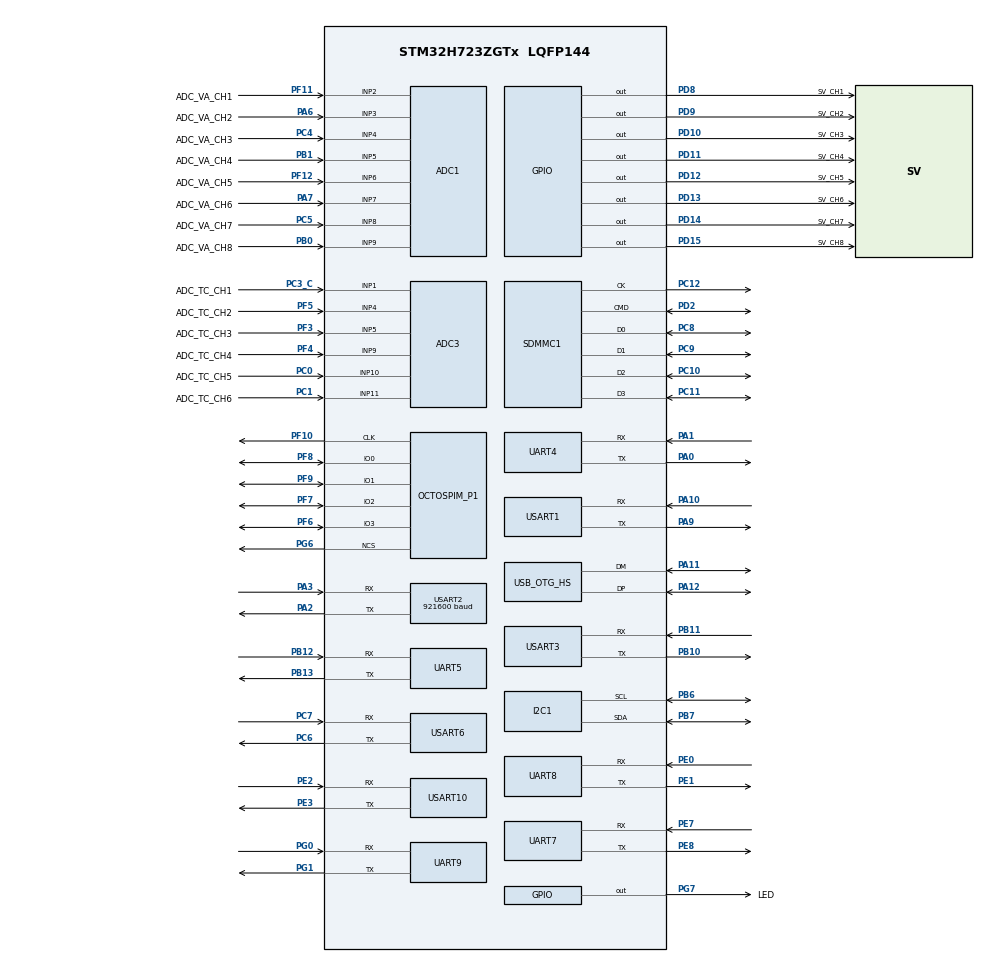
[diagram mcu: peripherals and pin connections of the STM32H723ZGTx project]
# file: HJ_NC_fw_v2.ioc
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ADC1.Channel-0\#ChannelRegularConversion=ADC_CHANNEL_2
ADC1.NbrOfConversionFlag=1
ADC1.OffsetNumber-0\#ChannelRegularConversion=ADC_OFFSET_NONE
ADC1.OffsetSignedSaturation-0\#ChannelRegularConversion=DISABLE
ADC1.Rank-0\#ChannelRegularConversion=1
ADC1.SamplingTime-0\#ChannelRegularConversion=ADC_SAMPLETIME_1CYCLE_5
ADC1.master=1
ADC3.Channel-0\#ChannelRegularConversion=ADC_CHANNEL_1
ADC3.NbrOfConversionFlag=1
ADC3.OffsetNumber-0\#ChannelRegularConversion=ADC_OFFSET_NONE
ADC3.OffsetSign-0\#ChannelRegularConversion=ADC3_OFFSET_SIGN_NEGATIVE
ADC3.Rank-0\#ChannelRegularConversion=1
ADC3.SamplingTime-0\#ChannelRegularConversion=ADC3_SAMPLETIME_2CYCLES_5
CORTEX_M7.default_mode_Activation=0
I2C1.Timing=0x60404E72
Mcu.Family=STM32H7
Mcu.Name=STM32H723ZGTx
Mcu.Package=LQFP144
NVIC.OTG_HS_IRQn=true\:0\:0\:false\:false\:true\:false\:true\:true
NVIC.PriorityGroup=NVIC_PRIORITYGROUP_4
NVIC.UART4_IRQn=true\:0\:0\:false\:false\:true\:true\:true\:true
NVIC.UART5_IRQn=true\:0\:0\:false\:false\:true\:true\:true\:true
NVIC.USART2_IRQn=true\:0\:0\:false\:false\:true\:true\:true\:true
NVIC.USART3_IRQn=true\:0\:0\:false\:false\:true\:true\:true\:true
OCTOSPI1.ClockMode=HAL_OSPI_CLOCK_MODE_3
OCTOSPI1.ClockPrescaler=2
OCTOSPI1.DeviceSize=23
OCTOSPI1.FifoThreshold=8
OCTOSPI1.FreeRunningClock=HAL_OSPI_FREERUNCLK_DISABLE
OCTOSPI1.SampleShifting=HAL_OSPI_SAMPLE_SHIFTING_HALFCYCLE
PA0.Mode=Asynchronous
PA0.Signal=UART4_TX
PA1.Mode=Asynchronous
PA1.Signal=UART4_RX
PA10.GPIO_Speed=GPIO_SPEED_FREQ_VERY_HIGH
PA10.Mode=Asynchronous
PA10.Signal=USART1_RX
PA11.Mode=Device_Only_FS
PA11.Signal=USB_OTG_HS_DM
PA12.Mode=Device_Only_FS
PA12.Signal=USB_OTG_HS_DP
PA13(JTMS/SWDIO).Mode=Serial_Wire
PA13(JTMS/SWDIO).Signal=DEBUG_JTMS-SWDIO
PA14(JTCK/SWCLK).Mode=Serial_Wire
PA14(JTCK/SWCLK).Signal=DEBUG_JTCK-SWCLK
PA2.Mode=Asynchronous
PA2.Signal=USART2_TX
PA3.Mode=Asynchronous
PA3.Signal=USART2_RX
PA6.GPIO_Label=ADC_VA_CH2
PA6.Signal=ADCx_INP3
PA7.GPIO_Label=ADC_VA_CH6
PA7.Signal=ADCx_INP7
PA9.GPIO_Speed=GPIO_SPEED_FREQ_VERY_HIGH
PA9.Mode=Asynchronous
PA9.Signal=USART1_TX
PB0.GPIO_Label=ADC_VA_CH8
PB0.Signal=ADCx_INP9
PB1.GPIO_Label=ADC_VA_CH4
PB1.Signal=ADCx_INP5
PB10.Mode=Asynchronous
PB10.Signal=USART3_TX
PB11.Mode=Asynchronous
PB11.Signal=USART3_RX
PB12.Mode=Asynchronous
PB12.Signal=UART5_RX
PB13.Mode=Asynchronous
PB13.Signal=UART5_TX
PB6.Mode=I2C
PB6.Signal=I2C1_SCL
PB7.Mode=I2C
PB7.Signal=I2C1_SDA
PC0.GPIO_Label=ADC_TC_CH5
PC0.Signal=ADCx_INP10
PC1.GPIO_Label=ADC_TC_CH6
PC1.Signal=ADCx_INP11
PC10.Mode=SD_4_bits_Wide_bus
PC10.Signal=SDMMC1_D2
PC11.Mode=SD_4_bits_Wide_bus
PC11.Signal=SDMMC1_D3
PC12.Mode=SD_4_bits_Wide_bus
PC12.Signal=SDMMC1_CK
PC14-OSC32_IN.Mode=LSE-External-Oscillator
PC14-OSC32_IN.Signal=RCC_OSC32_IN
PC15-OSC32_OUT.Mode=LSE-External-Oscillator
PC15-OSC32_OUT.Signal=RCC_OSC32_OUT
PC3_C.GPIO_Label=ADC_TC_CH1
PC3_C.Mode=IN1-Single-Ended
PC3_C.Signal=ADC3_INP1
PC4.GPIO_Label=ADC_VA_CH3
PC4.Signal=ADCx_INP4
PC5.GPIO_Label=ADC_VA_CH7
PC5.Signal=ADCx_INP8
PC6.Mode=Asynchronous
PC6.Signal=USART6_TX
PC7.Mode=Asynchronous
PC7.Signal=USART6_RX
PC8.Mode=SD_4_bits_Wide_bus
PC8.Signal=SDMMC1_D0
PC9.Mode=SD_4_bits_Wide_bus
PC9.Signal=SDMMC1_D1
PD10.GPIO_Label=SV_CH3
PD10.Signal=GPIO_Output
PD11.GPIO_Label=SV_CH4
PD11.Signal=GPIO_Output
PD12.GPIO_Label=SV_CH5
PD12.Signal=GPIO_Output
PD13.GPIO_Label=SV_CH6
PD13.Signal=GPIO_Output
PD14.GPIO_Label=SV_CH7
PD14.Signal=GPIO_Output
PD15.GPIO_Label=SV_CH8
PD15.Signal=GPIO_Output
PD2.Mode=SD_4_bits_Wide_bus
PD2.Signal=SDMMC1_CMD
PD8.GPIO_Label=SV_CH1
PD8.Signal=GPIO_Output
PD9.GPIO_Label=SV_CH2
PD9.Signal=GPIO_Output
PE0.Mode=Asynchronous
PE0.Signal=UART8_RX
PE1.Mode=Asynchronous
PE1.Signal=UART8_TX
PE2.Mode=Asynchronous
PE2.Signal=USART10_RX
PE3.Mode=Asynchronous
PE3.Signal=USART10_TX
PE7.Mode=Asynchronous
PE7.Signal=UART7_RX
PE8.Mode=Asynchronous
PE8.Signal=UART7_TX
PF10.Mode=O1_P1_CLK
PF10.Signal=OCTOSPIM_P1_CLK
PF11.GPIO_Label=ADC_VA_CH1
PF11.Mode=IN2-Single-Ended
PF11.Signal=ADC1_INP2
PF12.GPIO_Label=ADC_VA_CH5
PF12.Mode=IN6-Single-Ended
PF12.Signal=ADC1_INP6
PF3.GPIO_Label=ADC_TC_CH3
PF3.Mode=IN5-Single-Ended
PF3.Signal=ADC3_INP5
PF4.GPIO_Label=ADC_TC_CH4
PF4.Mode=IN9-Single-Ended
PF4.Signal=ADC3_INP9
PF5.GPIO_Label=ADC_TC_CH2
PF5.Mode=IN4-Single-Ended
PF5.Signal=ADC3_INP4
PF6.Mode=OCTOSPI1_IOL_Port1L
PF6.Signal=OCTOSPIM_P1_IO3
PF7.Mode=OCTOSPI1_IOL_Port1L
PF7.Signal=OCTOSPIM_P1_IO2
PF8.Mode=OCTOSPI1_IOL_Port1L
PF8.Signal=OCTOSPIM_P1_IO0
PF9.Mode=OCTOSPI1_IOL_Port1L
PF9.Signal=OCTOSPIM_P1_IO1
PG0.Mode=Asynchronous
PG0.Signal=UART9_RX
PG1.Mode=Asynchronous
PG1.Signal=UART9_TX
PG6.Mode=OCTOSPI1_Port1_NCS
PG6.Signal=OCTOSPIM_P1_NCS
PG7.GPIO_Label=LED
PG7.Signal=GPIO_Output
PH0-OSC_IN.Mode=HSE-External-Oscillator
PH0-OSC_IN.Signal=RCC_OSC_IN
PH1-OSC_OUT.Mode=HSE-External-Oscillator
PH1-OSC_OUT.Signal=RCC_OSC_OUT
ProjectManager.HeapSize=0x200
ProjectManager.StackSize=0x400
ProjectManager.TargetToolchain=STM32CubeIDE
RCC.ADCFreq_Value=100000000
RCC.APB1Freq_Value=137500000
RCC.APB2Freq_Value=137500000
RCC.APB3Freq_Value=137500000
RCC.APB4Freq_Value=137500000
RCC.CortexFreq_Value=550000000
RCC.D1PPRE=RCC_APB3_DIV2
RCC.D2PPRE1=RCC_APB1_DIV2
RCC.D2PPRE2=RCC_APB2_DIV2
RCC.D3PPRE=RCC_APB4_DIV2
RCC.DIVM1=10
RCC.DIVM2=16
RCC.DIVN1=220
RCC.DIVN2=128
RCC.DIVP1=1
RCC.DIVQ1=5
RCC.HCLKFreq_Value=275000000
RCC.HPRE=RCC_HCLK_DIV2
RCC.PLLSourceVirtual=RCC_PLLSOURCE_HSE
RCC.RTCClockSelection=RCC_RTCCLKSOURCE_LSE
RCC.SYSCLKFreq_VALUE=550000000
RCC.SYSCLKSource=RCC_SYSCLKSOURCE_PLLCLK
RCC.USBCLockSelection=RCC_USBCLKSOURCE_HSI48
RCC.USBFreq_Value=48000000
SDMMC1.ClockDiv=4
SH.ADCx_INP10.0=ADC3_INP10,IN10-Single-Ended
SH.ADCx_INP11.0=ADC3_INP11,IN11-Single-Ended
SH.ADCx_INP3.0=ADC1_INP3,IN3-Single-Ended
SH.ADCx_INP4.0=ADC1_INP4,IN4-Single-Ended
SH.ADCx_INP5.0=ADC1_INP5,IN5-Single-Ended
SH.ADCx_INP7.0=ADC1_INP7,IN7-Single-Ended
SH.ADCx_INP8.0=ADC1_INP8,IN8-Single-Ended
SH.ADCx_INP9.0=ADC1_INP9,IN9-Single-Ended
USART1.VirtualMode-Asynchronous=VM_ASYNC
USART10.VirtualMode-Asynchronous=VM_ASYNC
USART2.BaudRate=921600
USART2.VirtualMode-Asynchronous=VM_ASYNC
USART3.VirtualMode-Asynchronous=VM_ASYNC
USART6.VirtualMode-Asynchronous=VM_ASYNC
USB_DEVICE.CLASS_NAME_HS=CDC
USB_DEVICE.VirtualMode=Cdc
USB_DEVICE.VirtualModeHS=Cdc_HS
USB_OTG_HS.VirtualMode-Device_Only_FS=Device_Only_FS
VP_MEMORYMAP_VS_MEMORYMAP.Mode=CurAppReg
VP_OCTOSPI1_VS_quad.Mode=quad_mode
VP_RTC_VS_RTC_Activate.Mode=RTC_Enabled
VP_USB_DEVICE_VS_USB_DEVICE_CDC_HS.Mode=CDC_HS
board=custom

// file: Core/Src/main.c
/* USER CODE BEGIN Header */
/**
  ******************************************************************************
  * @file           : main.c
  * @brief          : Main program body
  ******************************************************************************
  * @attention
  *
  * Copyright (c) 2025 STMicroelectronics.
  * All rights reserved.
  *
  * This software is licensed under terms that can be found in the LICENSE file
  * in the root directory of this software component.
  * If no LICENSE file comes with this software, it is provided AS-IS.
  *
  ******************************************************************************
  */
/* USER CODE END Header */
#include "main.h"
#include "usb_device.h"

/* USER CODE BEGIN Includes */
#include "application.h"
/* USER CODE END Includes */

ADC_HandleTypeDef hadc1;
ADC_HandleTypeDef hadc3;

I2C_HandleTypeDef hi2c1;

OSPI_HandleTypeDef hospi1;

RTC_HandleTypeDef hrtc;

SD_HandleTypeDef hsd1;

UART_HandleTypeDef huart4;
UART_HandleTypeDef huart5;
UART_HandleTypeDef huart7;
UART_HandleTypeDef huart8;
UART_HandleTypeDef huart9;
UART_HandleTypeDef huart1;
UART_HandleTypeDef huart2;
UART_HandleTypeDef huart3;
UART_HandleTypeDef huart6;
UART_HandleTypeDef huart10;

void SystemClock_Config(void);
void PeriphCommonClock_Config(void);
static void MX_GPIO_Init(void);
static void MX_USART1_UART_Init(void);
static void MX_OCTOSPI1_Init(void);
static void MX_RTC_Init(void);
static void MX_SDMMC1_SD_Init(void);
static void MX_ADC1_Init(void);
static void MX_ADC3_Init(void);
static void MX_UART4_Init(void);
static void MX_UART5_Init(void);
static void MX_UART7_Init(void);
static void MX_UART8_Init(void);
static void MX_UART9_Init(void);
static void MX_USART2_UART_Init(void);
static void MX_USART3_UART_Init(void);
static void MX_USART6_UART_Init(void);
static void MX_USART10_UART_Init(void);
static void MX_I2C1_Init(void);

int main(void)
{

  /* MCU Configuration--------------------------------------------------------*/

  /* Reset of all peripherals, Initializes the Flash interface and the Systick. */
  HAL_Init();

  /* Configure the system clock */
  SystemClock_Config();

  /* Configure the peripherals common clocks */
  PeriphCommonClock_Config();

  /* Initialize all configured peripherals */
  MX_GPIO_Init();
  MX_USART1_UART_Init();
  MX_OCTOSPI1_Init();
  MX_RTC_Init();
  MX_SDMMC1_SD_Init();
  MX_USB_DEVICE_Init();
  MX_ADC1_Init();
  MX_ADC3_Init();
  MX_UART4_Init();
  MX_UART5_Init();
  MX_UART7_Init();
  MX_UART8_Init();
  MX_UART9_Init();
  MX_USART2_UART_Init();
  MX_USART3_UART_Init();
  MX_USART6_UART_Init();
  MX_USART10_UART_Init();
  MX_I2C1_Init();

  /* Infinite loop */
  /* USER CODE BEGIN WHILE */
  setup();
  while (1)
  {
	loop();
    /* USER CODE END WHILE */

  }
}

void SystemClock_Config(void)
{
  RCC_OscInitTypeDef RCC_OscInitStruct = {0};
  RCC_ClkInitTypeDef RCC_ClkInitStruct = {0};

  /** Supply configuration update enable
  */
  HAL_PWREx_ConfigSupply(PWR_LDO_SUPPLY);

  /** Configure the main internal regulator output voltage
  */
  __HAL_PWR_VOLTAGESCALING_CONFIG(PWR_REGULATOR_VOLTAGE_SCALE0);

  while(!__HAL_PWR_GET_FLAG(PWR_FLAG_VOSRDY)) {}

  /** Configure LSE Drive Capability
  */
  HAL_PWR_EnableBkUpAccess();
  __HAL_RCC_LSEDRIVE_CONFIG(RCC_LSEDRIVE_LOW);

  /** Initializes the RCC Oscillators according to the specified parameters
  * in the RCC_OscInitTypeDef structure.
  */
  RCC_OscInitStruct.OscillatorType = RCC_OSCILLATORTYPE_HSI48|RCC_OSCILLATORTYPE_HSE
                              |RCC_OSCILLATORTYPE_LSE;
  RCC_OscInitStruct.HSEState = RCC_HSE_ON;
  RCC_OscInitStruct.LSEState = RCC_LSE_ON;
  RCC_OscInitStruct.HSI48State = RCC_HSI48_ON;
  RCC_OscInitStruct.PLL.PLLState = RCC_PLL_ON;
  RCC_OscInitStruct.PLL.PLLSource = RCC_PLLSOURCE_HSE;
  RCC_OscInitStruct.PLL.PLLM = 10;
  RCC_OscInitStruct.PLL.PLLN = 220;
  RCC_OscInitStruct.PLL.PLLP = 1;
  RCC_OscInitStruct.PLL.PLLQ = 5;
  RCC_OscInitStruct.PLL.PLLR = 2;
  RCC_OscInitStruct.PLL.PLLRGE = RCC_PLL1VCIRANGE_1;
  RCC_OscInitStruct.PLL.PLLVCOSEL = RCC_PLL1VCOWIDE;
  RCC_OscInitStruct.PLL.PLLFRACN = 0;
  if (HAL_RCC_OscConfig(&RCC_OscInitStruct) != HAL_OK)
  {
    Error_Handler();
  }

  /** Initializes the CPU, AHB and APB buses clocks
  */
  RCC_ClkInitStruct.ClockType = RCC_CLOCKTYPE_HCLK|RCC_CLOCKTYPE_SYSCLK
                              |RCC_CLOCKTYPE_PCLK1|RCC_CLOCKTYPE_PCLK2
                              |RCC_CLOCKTYPE_D3PCLK1|RCC_CLOCKTYPE_D1PCLK1;
  RCC_ClkInitStruct.SYSCLKSource = RCC_SYSCLKSOURCE_PLLCLK;
  RCC_ClkInitStruct.SYSCLKDivider = RCC_SYSCLK_DIV1;
  RCC_ClkInitStruct.AHBCLKDivider = RCC_HCLK_DIV2;
  RCC_ClkInitStruct.APB3CLKDivider = RCC_APB3_DIV2;
  RCC_ClkInitStruct.APB1CLKDivider = RCC_APB1_DIV2;
  RCC_ClkInitStruct.APB2CLKDivider = RCC_APB2_DIV2;
  RCC_ClkInitStruct.APB4CLKDivider = RCC_APB4_DIV2;

  if (HAL_RCC_ClockConfig(&RCC_ClkInitStruct, FLASH_LATENCY_3) != HAL_OK)
  {
    Error_Handler();
  }
}

void PeriphCommonClock_Config(void)
{
  RCC_PeriphCLKInitTypeDef PeriphClkInitStruct = {0};

  /** Initializes the peripherals clock
  */
  PeriphClkInitStruct.PeriphClockSelection = RCC_PERIPHCLK_ADC;
  PeriphClkInitStruct.PLL2.PLL2M = 16;
  PeriphClkInitStruct.PLL2.PLL2N = 128;
  PeriphClkInitStruct.PLL2.PLL2P = 2;
  PeriphClkInitStruct.PLL2.PLL2Q = 2;
  PeriphClkInitStruct.PLL2.PLL2R = 2;
  PeriphClkInitStruct.PLL2.PLL2RGE = RCC_PLL2VCIRANGE_0;
  PeriphClkInitStruct.PLL2.PLL2VCOSEL = RCC_PLL2VCOMEDIUM;
  PeriphClkInitStruct.PLL2.PLL2FRACN = 0;
  PeriphClkInitStruct.AdcClockSelection = RCC_ADCCLKSOURCE_PLL2;
  if (HAL_RCCEx_PeriphCLKConfig(&PeriphClkInitStruct) != HAL_OK)
  {
    Error_Handler();
  }
}

static void MX_ADC1_Init(void)
{

  ADC_MultiModeTypeDef multimode = {0};
  ADC_ChannelConfTypeDef sConfig = {0};

  /** Common config
  */
  hadc1.Instance = ADC1;
  hadc1.Init.ClockPrescaler = ADC_CLOCK_ASYNC_DIV1;
  hadc1.Init.Resolution = ADC_RESOLUTION_16B;
  hadc1.Init.ScanConvMode = ADC_SCAN_DISABLE;
  hadc1.Init.EOCSelection = ADC_EOC_SINGLE_CONV;
  hadc1.Init.LowPowerAutoWait = DISABLE;
  hadc1.Init.ContinuousConvMode = DISABLE;
  hadc1.Init.NbrOfConversion = 1;
  hadc1.Init.DiscontinuousConvMode = DISABLE;
  hadc1.Init.ExternalTrigConv = ADC_SOFTWARE_START;
  hadc1.Init.ExternalTrigConvEdge = ADC_EXTERNALTRIGCONVEDGE_NONE;
  hadc1.Init.ConversionDataManagement = ADC_CONVERSIONDATA_DR;
  hadc1.Init.Overrun = ADC_OVR_DATA_PRESERVED;
  hadc1.Init.LeftBitShift = ADC_LEFTBITSHIFT_NONE;
  hadc1.Init.OversamplingMode = DISABLE;
  hadc1.Init.Oversampling.Ratio = 1;
  if (HAL_ADC_Init(&hadc1) != HAL_OK)
  {
    Error_Handler();
  }

  /** Configure the ADC multi-mode
  */
  multimode.Mode = ADC_MODE_INDEPENDENT;
  if (HAL_ADCEx_MultiModeConfigChannel(&hadc1, &multimode) != HAL_OK)
  {
    Error_Handler();
  }

  /** Configure Regular Channel
  */
  sConfig.Channel = ADC_CHANNEL_2;
  sConfig.Rank = ADC_REGULAR_RANK_1;
  sConfig.SamplingTime = ADC_SAMPLETIME_1CYCLE_5;
  sConfig.SingleDiff = ADC_SINGLE_ENDED;
  sConfig.OffsetNumber = ADC_OFFSET_NONE;
  sConfig.Offset = 0;
  sConfig.OffsetSignedSaturation = DISABLE;
  if (HAL_ADC_ConfigChannel(&hadc1, &sConfig) != HAL_OK)
  {
    Error_Handler();
  }

}

static void MX_ADC3_Init(void)
{

  ADC_ChannelConfTypeDef sConfig = {0};

  /** Common config
  */
  hadc3.Instance = ADC3;
  hadc3.Init.ClockPrescaler = ADC_CLOCK_ASYNC_DIV1;
  hadc3.Init.Resolution = ADC_RESOLUTION_12B;
  hadc3.Init.DataAlign = ADC3_DATAALIGN_RIGHT;
  hadc3.Init.ScanConvMode = ADC_SCAN_DISABLE;
  hadc3.Init.EOCSelection = ADC_EOC_SINGLE_CONV;
  hadc3.Init.LowPowerAutoWait = DISABLE;
  hadc3.Init.ContinuousConvMode = DISABLE;
  hadc3.Init.NbrOfConversion = 1;
  hadc3.Init.DiscontinuousConvMode = DISABLE;
  hadc3.Init.ExternalTrigConv = ADC_SOFTWARE_START;
  hadc3.Init.ExternalTrigConvEdge = ADC_EXTERNALTRIGCONVEDGE_NONE;
  hadc3.Init.DMAContinuousRequests = DISABLE;
  hadc3.Init.SamplingMode = ADC_SAMPLING_MODE_NORMAL;
  hadc3.Init.ConversionDataManagement = ADC_CONVERSIONDATA_DR;
  hadc3.Init.Overrun = ADC_OVR_DATA_PRESERVED;
  hadc3.Init.LeftBitShift = ADC_LEFTBITSHIFT_NONE;
  hadc3.Init.OversamplingMode = DISABLE;
  hadc3.Init.Oversampling.Ratio = ADC3_OVERSAMPLING_RATIO_2;
  if (HAL_ADC_Init(&hadc3) != HAL_OK)
  {
    Error_Handler();
  }

  /** Configure Regular Channel
  */
  sConfig.Channel = ADC_CHANNEL_1;
  sConfig.Rank = ADC_REGULAR_RANK_1;
  sConfig.SamplingTime = ADC3_SAMPLETIME_2CYCLES_5;
  sConfig.SingleDiff = ADC_SINGLE_ENDED;
  sConfig.OffsetNumber = ADC_OFFSET_NONE;
  sConfig.Offset = 0;
  sConfig.OffsetSign = ADC3_OFFSET_SIGN_NEGATIVE;
  if (HAL_ADC_ConfigChannel(&hadc3, &sConfig) != HAL_OK)
  {
    Error_Handler();
  }

}

static void MX_I2C1_Init(void)
{

  hi2c1.Instance = I2C1;
  hi2c1.Init.Timing = 0x60404E72;
  hi2c1.Init.OwnAddress1 = 0;
  hi2c1.Init.AddressingMode = I2C_ADDRESSINGMODE_7BIT;
  hi2c1.Init.DualAddressMode = I2C_DUALADDRESS_DISABLE;
  hi2c1.Init.OwnAddress2 = 0;
  hi2c1.Init.OwnAddress2Masks = I2C_OA2_NOMASK;
  hi2c1.Init.GeneralCallMode = I2C_GENERALCALL_DISABLE;
  hi2c1.Init.NoStretchMode = I2C_NOSTRETCH_DISABLE;
  if (HAL_I2C_Init(&hi2c1) != HAL_OK)
  {
    Error_Handler();
  }

  /** Configure Analogue filter
  */
  if (HAL_I2CEx_ConfigAnalogFilter(&hi2c1, I2C_ANALOGFILTER_ENABLE) != HAL_OK)
  {
    Error_Handler();
  }

  /** Configure Digital filter
  */
  if (HAL_I2CEx_ConfigDigitalFilter(&hi2c1, 0) != HAL_OK)
  {
    Error_Handler();
  }

}

static void MX_OCTOSPI1_Init(void)
{

  OSPIM_CfgTypeDef sOspiManagerCfg = {0};

  /* OCTOSPI1 parameter configuration*/
  hospi1.Instance = OCTOSPI1;
  hospi1.Init.FifoThreshold = 8;
  hospi1.Init.DualQuad = HAL_OSPI_DUALQUAD_DISABLE;
  hospi1.Init.MemoryType = HAL_OSPI_MEMTYPE_MICRON;
  hospi1.Init.DeviceSize = 23;
  hospi1.Init.ChipSelectHighTime = 1;
  hospi1.Init.FreeRunningClock = HAL_OSPI_FREERUNCLK_DISABLE;
  hospi1.Init.ClockMode = HAL_OSPI_CLOCK_MODE_3;
  hospi1.Init.WrapSize = HAL_OSPI_WRAP_NOT_SUPPORTED;
  hospi1.Init.ClockPrescaler = 2;
  hospi1.Init.SampleShifting = HAL_OSPI_SAMPLE_SHIFTING_HALFCYCLE;
  hospi1.Init.DelayHoldQuarterCycle = HAL_OSPI_DHQC_DISABLE;
  hospi1.Init.ChipSelectBoundary = 0;
  hospi1.Init.DelayBlockBypass = HAL_OSPI_DELAY_BLOCK_BYPASSED;
  hospi1.Init.MaxTran = 0;
  hospi1.Init.Refresh = 0;
  if (HAL_OSPI_Init(&hospi1) != HAL_OK)
  {
    Error_Handler();
  }
  sOspiManagerCfg.ClkPort = 1;
  sOspiManagerCfg.NCSPort = 1;
  sOspiManagerCfg.IOLowPort = HAL_OSPIM_IOPORT_1_LOW;
  if (HAL_OSPIM_Config(&hospi1, &sOspiManagerCfg, HAL_OSPI_TIMEOUT_DEFAULT_VALUE) != HAL_OK)
  {
    Error_Handler();
  }

}

static void MX_RTC_Init(void)
{

  /** Initialize RTC Only
  */
  hrtc.Instance = RTC;
  hrtc.Init.HourFormat = RTC_HOURFORMAT_24;
  hrtc.Init.AsynchPrediv = 127;
  hrtc.Init.SynchPrediv = 255;
  hrtc.Init.OutPut = RTC_OUTPUT_DISABLE;
  hrtc.Init.OutPutPolarity = RTC_OUTPUT_POLARITY_HIGH;
  hrtc.Init.OutPutType = RTC_OUTPUT_TYPE_OPENDRAIN;
  hrtc.Init.OutPutRemap = RTC_OUTPUT_REMAP_NONE;
  if (HAL_RTC_Init(&hrtc) != HAL_OK)
  {
    Error_Handler();
  }

}

static void MX_SDMMC1_SD_Init(void)
{

  hsd1.Instance = SDMMC1;
  hsd1.Init.ClockEdge = SDMMC_CLOCK_EDGE_RISING;
  hsd1.Init.ClockPowerSave = SDMMC_CLOCK_POWER_SAVE_DISABLE;
  hsd1.Init.BusWide = SDMMC_BUS_WIDE_4B;
  hsd1.Init.HardwareFlowControl = SDMMC_HARDWARE_FLOW_CONTROL_DISABLE;
  hsd1.Init.ClockDiv = 4;
  if (HAL_SD_Init(&hsd1) != HAL_OK)
  {
    Error_Handler();
  }

}

static void MX_UART4_Init(void)
{

  huart4.Instance = UART4;
  huart4.Init.BaudRate = 115200;
  huart4.Init.WordLength = UART_WORDLENGTH_8B;
  huart4.Init.StopBits = UART_STOPBITS_1;
  huart4.Init.Parity = UART_PARITY_NONE;
  huart4.Init.Mode = UART_MODE_TX_RX;
  huart4.Init.HwFlowCtl = UART_HWCONTROL_NONE;
  huart4.Init.OverSampling = UART_OVERSAMPLING_16;
  huart4.Init.OneBitSampling = UART_ONE_BIT_SAMPLE_DISABLE;
  huart4.Init.ClockPrescaler = UART_PRESCALER_DIV1;
  huart4.AdvancedInit.AdvFeatureInit = UART_ADVFEATURE_NO_INIT;
  if (HAL_UART_Init(&huart4) != HAL_OK)
  {
    Error_Handler();
  }
  if (HAL_UARTEx_SetTxFifoThreshold(&huart4, UART_TXFIFO_THRESHOLD_1_8) != HAL_OK)
  {
    Error_Handler();
  }
  if (HAL_UARTEx_SetRxFifoThreshold(&huart4, UART_RXFIFO_THRESHOLD_1_8) != HAL_OK)
  {
    Error_Handler();
  }
  if (HAL_UARTEx_DisableFifoMode(&huart4) != HAL_OK)
  {
    Error_Handler();
  }

}

static void MX_UART5_Init(void)
{

  huart5.Instance = UART5;
  huart5.Init.BaudRate = 115200;
  huart5.Init.WordLength = UART_WORDLENGTH_8B;
  huart5.Init.StopBits = UART_STOPBITS_1;
  huart5.Init.Parity = UART_PARITY_NONE;
  huart5.Init.Mode = UART_MODE_TX_RX;
  huart5.Init.HwFlowCtl = UART_HWCONTROL_NONE;
  huart5.Init.OverSampling = UART_OVERSAMPLING_16;
  huart5.Init.OneBitSampling = UART_ONE_BIT_SAMPLE_DISABLE;
  huart5.Init.ClockPrescaler = UART_PRESCALER_DIV1;
  huart5.AdvancedInit.AdvFeatureInit = UART_ADVFEATURE_NO_INIT;
  if (HAL_UART_Init(&huart5) != HAL_OK)
  {
    Error_Handler();
  }
  if (HAL_UARTEx_SetTxFifoThreshold(&huart5, UART_TXFIFO_THRESHOLD_1_8) != HAL_OK)
  {
    Error_Handler();
  }
  if (HAL_UARTEx_SetRxFifoThreshold(&huart5, UART_RXFIFO_THRESHOLD_1_8) != HAL_OK)
  {
    Error_Handler();
  }
  if (HAL_UARTEx_DisableFifoMode(&huart5) != HAL_OK)
  {
    Error_Handler();
  }

}

static void MX_UART7_Init(void)
{

  huart7.Instance = UART7;
  huart7.Init.BaudRate = 115200;
  huart7.Init.WordLength = UART_WORDLENGTH_8B;
  huart7.Init.StopBits = UART_STOPBITS_1;
  huart7.Init.Parity = UART_PARITY_NONE;
  huart7.Init.Mode = UART_MODE_TX_RX;
  huart7.Init.HwFlowCtl = UART_HWCONTROL_NONE;
  huart7.Init.OverSampling = UART_OVERSAMPLING_16;
  huart7.Init.OneBitSampling = UART_ONE_BIT_SAMPLE_DISABLE;
  huart7.Init.ClockPrescaler = UART_PRESCALER_DIV1;
  huart7.AdvancedInit.AdvFeatureInit = UART_ADVFEATURE_NO_INIT;
  if (HAL_UART_Init(&huart7) != HAL_OK)
  {
    Error_Handler();
  }
  if (HAL_UARTEx_SetTxFifoThreshold(&huart7, UART_TXFIFO_THRESHOLD_1_8) != HAL_OK)
  {
    Error_Handler();
  }
  if (HAL_UARTEx_SetRxFifoThreshold(&huart7, UART_RXFIFO_THRESHOLD_1_8) != HAL_OK)
  {
    Error_Handler();
  }
  if (HAL_UARTEx_DisableFifoMode(&huart7) != HAL_OK)
  {
    Error_Handler();
  }

}

static void MX_UART8_Init(void)
{

  huart8.Instance = UART8;
  huart8.Init.BaudRate = 115200;
  huart8.Init.WordLength = UART_WORDLENGTH_8B;
  huart8.Init.StopBits = UART_STOPBITS_1;
  huart8.Init.Parity = UART_PARITY_NONE;
  huart8.Init.Mode = UART_MODE_TX_RX;
  huart8.Init.HwFlowCtl = UART_HWCONTROL_NONE;
  huart8.Init.OverSampling = UART_OVERSAMPLING_16;
  huart8.Init.OneBitSampling = UART_ONE_BIT_SAMPLE_DISABLE;
  huart8.Init.ClockPrescaler = UART_PRESCALER_DIV1;
  huart8.AdvancedInit.AdvFeatureInit = UART_ADVFEATURE_NO_INIT;
  if (HAL_UART_Init(&huart8) != HAL_OK)
  {
    Error_Handler();
  }
  if (HAL_UARTEx_SetTxFifoThreshold(&huart8, UART_TXFIFO_THRESHOLD_1_8) != HAL_OK)
  {
    Error_Handler();
  }
  if (HAL_UARTEx_SetRxFifoThreshold(&huart8, UART_RXFIFO_THRESHOLD_1_8) != HAL_OK)
  {
    Error_Handler();
  }
  if (HAL_UARTEx_DisableFifoMode(&huart8) != HAL_OK)
  {
    Error_Handler();
  }

}

static void MX_UART9_Init(void)
{

  huart9.Instance = UART9;
  huart9.Init.BaudRate = 115200;
  huart9.Init.WordLength = UART_WORDLENGTH_8B;
  huart9.Init.StopBits = UART_STOPBITS_1;
  huart9.Init.Parity = UART_PARITY_NONE;
  huart9.Init.Mode = UART_MODE_TX_RX;
  huart9.Init.HwFlowCtl = UART_HWCONTROL_NONE;
  huart9.Init.OverSampling = UART_OVERSAMPLING_16;
  huart9.Init.OneBitSampling = UART_ONE_BIT_SAMPLE_DISABLE;
  huart9.Init.ClockPrescaler = UART_PRESCALER_DIV1;
  huart9.AdvancedInit.AdvFeatureInit = UART_ADVFEATURE_NO_INIT;
  if (HAL_UART_Init(&huart9) != HAL_OK)
  {
    Error_Handler();
  }
  if (HAL_UARTEx_SetTxFifoThreshold(&huart9, UART_TXFIFO_THRESHOLD_1_8) != HAL_OK)
  {
    Error_Handler();
  }
  if (HAL_UARTEx_SetRxFifoThreshold(&huart9, UART_RXFIFO_THRESHOLD_1_8) != HAL_OK)
  {
    Error_Handler();
  }
  if (HAL_UARTEx_DisableFifoMode(&huart9) != HAL_OK)
  {
    Error_Handler();
  }

}

static void MX_USART1_UART_Init(void)
{

  huart1.Instance = USART1;
  huart1.Init.BaudRate = 115200;
  huart1.Init.WordLength = UART_WORDLENGTH_8B;
  huart1.Init.StopBits = UART_STOPBITS_1;
  huart1.Init.Parity = UART_PARITY_NONE;
  huart1.Init.Mode = UART_MODE_TX_RX;
  huart1.Init.HwFlowCtl = UART_HWCONTROL_NONE;
  huart1.Init.OverSampling = UART_OVERSAMPLING_16;
  huart1.Init.OneBitSampling = UART_ONE_BIT_SAMPLE_DISABLE;
  huart1.Init.ClockPrescaler = UART_PRESCALER_DIV1;
  huart1.AdvancedInit.AdvFeatureInit = UART_ADVFEATURE_NO_INIT;
  if (HAL_UART_Init(&huart1) != HAL_OK)
  {
    Error_Handler();
  }
  if (HAL_UARTEx_SetTxFifoThreshold(&huart1, UART_TXFIFO_THRESHOLD_1_8) != HAL_OK)
  {
    Error_Handler();
  }
  if (HAL_UARTEx_SetRxFifoThreshold(&huart1, UART_RXFIFO_THRESHOLD_1_8) != HAL_OK)
  {
    Error_Handler();
  }
  if (HAL_UARTEx_DisableFifoMode(&huart1) != HAL_OK)
  {
    Error_Handler();
  }

}

static void MX_USART2_UART_Init(void)
{

  huart2.Instance = USART2;
  huart2.Init.BaudRate = 921600;
  huart2.Init.WordLength = UART_WORDLENGTH_8B;
  huart2.Init.StopBits = UART_STOPBITS_1;
  huart2.Init.Parity = UART_PARITY_NONE;
  huart2.Init.Mode = UART_MODE_TX_RX;
  huart2.Init.HwFlowCtl = UART_HWCONTROL_NONE;
  huart2.Init.OverSampling = UART_OVERSAMPLING_16;
  huart2.Init.OneBitSampling = UART_ONE_BIT_SAMPLE_DISABLE;
  huart2.Init.ClockPrescaler = UART_PRESCALER_DIV1;
  huart2.AdvancedInit.AdvFeatureInit = UART_ADVFEATURE_NO_INIT;
  if (HAL_UART_Init(&huart2) != HAL_OK)
  {
    Error_Handler();
  }
  if (HAL_UARTEx_SetTxFifoThreshold(&huart2, UART_TXFIFO_THRESHOLD_1_8) != HAL_OK)
  {
    Error_Handler();
  }
  if (HAL_UARTEx_SetRxFifoThreshold(&huart2, UART_RXFIFO_THRESHOLD_1_8) != HAL_OK)
  {
    Error_Handler();
  }
  if (HAL_UARTEx_DisableFifoMode(&huart2) != HAL_OK)
  {
    Error_Handler();
  }

}

static void MX_USART3_UART_Init(void)
{

  huart3.Instance = USART3;
  huart3.Init.BaudRate = 115200;
  huart3.Init.WordLength = UART_WORDLENGTH_8B;
  huart3.Init.StopBits = UART_STOPBITS_1;
  huart3.Init.Parity = UART_PARITY_NONE;
  huart3.Init.Mode = UART_MODE_TX_RX;
  huart3.Init.HwFlowCtl = UART_HWCONTROL_NONE;
  huart3.Init.OverSampling = UART_OVERSAMPLING_16;
  huart3.Init.OneBitSampling = UART_ONE_BIT_SAMPLE_DISABLE;
  huart3.Init.ClockPrescaler = UART_PRESCALER_DIV1;
  huart3.AdvancedInit.AdvFeatureInit = UART_ADVFEATURE_NO_INIT;
  if (HAL_UART_Init(&huart3) != HAL_OK)
  {
    Error_Handler();
  }
  if (HAL_UARTEx_SetTxFifoThreshold(&huart3, UART_TXFIFO_THRESHOLD_1_8) != HAL_OK)
  {
    Error_Handler();
  }
  if (HAL_UARTEx_SetRxFifoThreshold(&huart3, UART_RXFIFO_THRESHOLD_1_8) != HAL_OK)
  {
    Error_Handler();
  }
  if (HAL_UARTEx_DisableFifoMode(&huart3) != HAL_OK)
  {
    Error_Handler();
  }

}

static void MX_USART6_UART_Init(void)
{

  huart6.Instance = USART6;
  huart6.Init.BaudRate = 115200;
  huart6.Init.WordLength = UART_WORDLENGTH_8B;
  huart6.Init.StopBits = UART_STOPBITS_1;
  huart6.Init.Parity = UART_PARITY_NONE;
  huart6.Init.Mode = UART_MODE_TX_RX;
  huart6.Init.HwFlowCtl = UART_HWCONTROL_NONE;
  huart6.Init.OverSampling = UART_OVERSAMPLING_16;
  huart6.Init.OneBitSampling = UART_ONE_BIT_SAMPLE_DISABLE;
  huart6.Init.ClockPrescaler = UART_PRESCALER_DIV1;
  huart6.AdvancedInit.AdvFeatureInit = UART_ADVFEATURE_NO_INIT;
  if (HAL_UART_Init(&huart6) != HAL_OK)
  {
    Error_Handler();
  }
  if (HAL_UARTEx_SetTxFifoThreshold(&huart6, UART_TXFIFO_THRESHOLD_1_8) != HAL_OK)
  {
    Error_Handler();
  }
  if (HAL_UARTEx_SetRxFifoThreshold(&huart6, UART_RXFIFO_THRESHOLD_1_8) != HAL_OK)
  {
    Error_Handler();
  }
  if (HAL_UARTEx_DisableFifoMode(&huart6) != HAL_OK)
  {
    Error_Handler();
  }

}

static void MX_USART10_UART_Init(void)
{

  huart10.Instance = USART10;
  huart10.Init.BaudRate = 115200;
  huart10.Init.WordLength = UART_WORDLENGTH_8B;
  huart10.Init.StopBits = UART_STOPBITS_1;
  huart10.Init.Parity = UART_PARITY_NONE;
  huart10.Init.Mode = UART_MODE_TX_RX;
  huart10.Init.HwFlowCtl = UART_HWCONTROL_NONE;
  huart10.Init.OverSampling = UART_OVERSAMPLING_16;
  huart10.Init.OneBitSampling = UART_ONE_BIT_SAMPLE_DISABLE;
  huart10.Init.ClockPrescaler = UART_PRESCALER_DIV1;
  huart10.AdvancedInit.AdvFeatureInit = UART_ADVFEATURE_NO_INIT;
  if (HAL_UART_Init(&huart10) != HAL_OK)
  {
    Error_Handler();
  }
  if (HAL_UARTEx_SetTxFifoThreshold(&huart10, UART_TXFIFO_THRESHOLD_1_8) != HAL_OK)
  {
    Error_Handler();
  }
  if (HAL_UARTEx_SetRxFifoThreshold(&huart10, UART_RXFIFO_THRESHOLD_1_8) != HAL_OK)
  {
    Error_Handler();
  }
  if (HAL_UARTEx_DisableFifoMode(&huart10) != HAL_OK)
  {
    Error_Handler();
  }

}

static void MX_GPIO_Init(void)
{
  GPIO_InitTypeDef GPIO_InitStruct = {0};

  /* GPIO Ports Clock Enable */
  __HAL_RCC_GPIOE_CLK_ENABLE();
  __HAL_RCC_GPIOC_CLK_ENABLE();
  __HAL_RCC_GPIOF_CLK_ENABLE();
  __HAL_RCC_GPIOH_CLK_ENABLE();
  __HAL_RCC_GPIOA_CLK_ENABLE();
  __HAL_RCC_GPIOB_CLK_ENABLE();
  __HAL_RCC_GPIOG_CLK_ENABLE();
  __HAL_RCC_GPIOD_CLK_ENABLE();

  /*Configure GPIO pin Output Level */
  HAL_GPIO_WritePin(GPIOD, SV_CH1_Pin|SV_CH2_Pin|SV_CH3_Pin|SV_CH4_Pin
                          |SV_CH5_Pin|SV_CH6_Pin|SV_CH7_Pin|SV_CH8_Pin, GPIO_PIN_RESET);

  /*Configure GPIO pin Output Level */
  HAL_GPIO_WritePin(LED_GPIO_Port, LED_Pin, GPIO_PIN_RESET);

  /*Configure GPIO pins : SV_CH1_Pin SV_CH2_Pin SV_CH3_Pin SV_CH4_Pin
                           SV_CH5_Pin SV_CH6_Pin SV_CH7_Pin SV_CH8_Pin */
  GPIO_InitStruct.Pin = SV_CH1_Pin|SV_CH2_Pin|SV_CH3_Pin|SV_CH4_Pin
                          |SV_CH5_Pin|SV_CH6_Pin|SV_CH7_Pin|SV_CH8_Pin;
  GPIO_InitStruct.Mode = GPIO_MODE_OUTPUT_PP;
  GPIO_InitStruct.Pull = GPIO_NOPULL;
  GPIO_InitStruct.Speed = GPIO_SPEED_FREQ_LOW;
  HAL_GPIO_Init(GPIOD, &GPIO_InitStruct);

  /*Configure GPIO pin : LED_Pin */
  GPIO_InitStruct.Pin = LED_Pin;
  GPIO_InitStruct.Mode = GPIO_MODE_OUTPUT_PP;
  GPIO_InitStruct.Pull = GPIO_NOPULL;
  GPIO_InitStruct.Speed = GPIO_SPEED_FREQ_LOW;
  HAL_GPIO_Init(LED_GPIO_Port, &GPIO_InitStruct);

}

void Error_Handler(void)
{
  __disable_irq();
  while (1)
  {
  }
}
